# MCXN947_cm33_core0 register map
Vendor: nxp.com; File version: 1.0
CPU: CM33 r2p0, little endian, MPU, FPU, VTOR, 3 interrupt priority bits
Registers are 32-bit, read-write, reset 0x0 unless marked. A register's access mark holds for its fields unless they carry their own. Offsets are from the block's base; [hi:lo] are bit positions; {n}, {i} and the like mark numbered series; 'fields as' and 'values as' point back to an identical list.

## FLEXSPI0 — FlexSPI
Base 0x400C8000
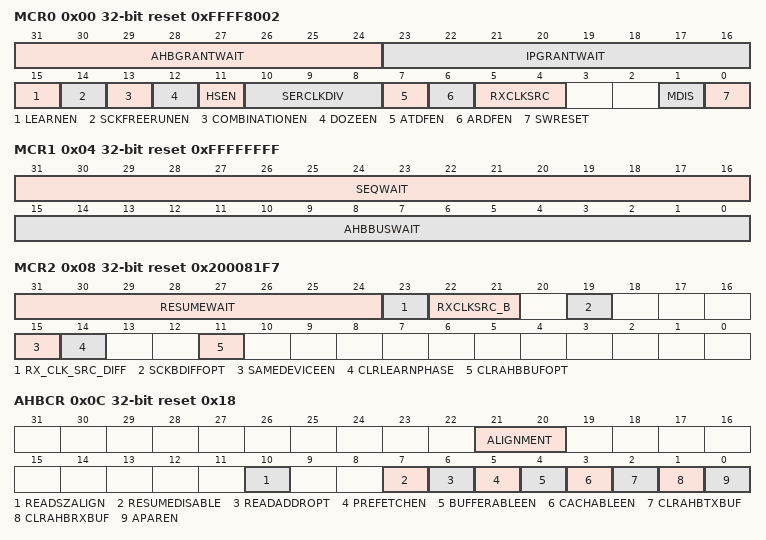
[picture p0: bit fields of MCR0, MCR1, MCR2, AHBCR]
0x00 MCR0 reset 0xFFFF8002 — Module Control 0
  [31:24] AHBGRANTWAIT — Timeouts Wait Cycle for AHB command Grant
  [23:16] IPGRANTWAIT — Timeout Wait Cycle for IP Command Grant
  [15] LEARNEN — Data Learning Enable
    0=DISABLE; 1=ENABLE
  [14] SCKFREERUNEN — SCLK Free-running Enable
    0=DISABLE; 1=ENABLE
  [13] COMBINATIONEN — Combination Mode Enable
    0=DISABLE; 1=ENABLE
  [12] DOZEEN — Doze Mode Enable
    0=Disable; 1=Enable
  [11] HSEN — Half Speed Serial Flash Memory Access Enable
    0=Disable; 1=Enable
  [10:8] SERCLKDIV — Serial Root Clock Divider
    {v}=Divided by {v+1} (v=0..7)
  [7] ATDFEN — AHB Write Access to IP Transmit FIFO Enable
    0=AHB write access disabled. IP bus writes to IP transmit FIFO. AHB bus write access to IP transmit FIFO memory space produces bus error.; 1=AHB write access enabled. AHB bus writes to IP transmit FIFO. IP Bus write access to IP transmit FIFO memory space is ignored and causes no bus error.
  [6] ARDFEN — AHB Read Access to IP Receive FIFO Enable
    0=AHB read access disabled. IP bus reads IP receive FIFO. AHB Bus read access to IP receive FIFO memory space produces bus error.; 1=AHB read access enabled. AHB bus reads IP receive FIFO. IP Bus read access to IP receive FIFO memory space returns data zero and causes no bus error.
  [5:4] RXCLKSRC — Sample Clock Source for Flash Reading
    0=Dummy Read strobe that FlexSPI generates, looped back internally; 1=Dummy Read strobe that FlexSPI generates, looped back from DQS pad; 2=SCLK output clock and looped back from SCLK pad; 3=Flash-memory-provided read strobe and input from DQS pad
  [1] MDIS — Module Disable
    0=No impact; 1=Module disable
  [0] SWRESET — Software Reset
    0=No impact; 1=Software reset
0x04 MCR1 reset 0xFFFFFFFF — Module Control 1
  [31:16] SEQWAIT — Command Sequence Wait
  [15:0] AHBBUSWAIT
0x08 MCR2 reset 0x200081F7 — Module Control 2
  [31:24] RESUMEWAIT — Resume Wait Duration
  [23] RX_CLK_SRC_DIFF — Sample Clock Source Different
    0=Use MCR0[RXCLKSRC] for Port A and Port B; 1=Use MCR0[RXCLKSRC] for Port A, and MCR2[RXCLKSRC_B] for Port B
  [22:21] RXCLKSRC_B — Port B Receiver Clock Source
    0=Dummy read strobe that FlexSPI generates, looped back internally; 1=Dummy read strobe that FlexSPI generates, looped back from DQS pad; 2=SCLK output clock and looped back from SCLK pad; 3=Flash-memory-provided read strobe and input from DQS pad
  [19] SCKBDIFFOPT — SCLK Port B Differential Output
    0=Use B_SCLK pad as port B SCLK clock output. Port B flash memory access is available.; 1=Use B_SCLK pad as port A SCLK inverted clock output (Differential clock to A_SCLK). Port B flash memory access is not available.
  [15] SAMEDEVICEEN — Same Device Enable
    0=individual_parallel (In Individual mode, FLSHA1CRx and FLSHA2CRx, FLSHB1CRx and FLSHB2CRx settings are applied to Flash A1, A2, B1, B2 separately. In Parallel mode, FLSHA1CRx register setting is applied to Flash A1 and B1, FLSHA2CRx register setting is applied to Flash A2 and B2. FLSHB1CRx and FLSHB2CRx register settings are ignored.); 1=ENABLE (FLSHA1CR0, FLSHA1CR1, and FLSHA1CR2 register settings are applied to Flash A1, A2, B1, B2. FLSHA2CRx, FLSHB1CRx, and FLSHB2CRx settings are ignored.)
  [14] CLRLEARNPHASE — Clear Learn Phase Selection
    0=No impact; 1=Reset sample clock phase selection to 0
  [11] CLRAHBBUFOPT — Clear AHB Buffer
    0=Not cleared automatically; 1=Cleared automatically
0x0C AHBCR reset 0x18 — AHB Bus Control
  [21:20] ALIGNMENT — AHB Boundary Alignment
    0=bit0 (No limit); 1=bit1 (1 KB); 2=bit2 (512 bytes); 3=bit3 (256 bytes)
  [10] READSZALIGN — AHB Read Size Alignment
    0=Register settings such as PREFETCH_EN determine AHB read size; 1=AHB read size to up size to 8 bytes aligned, no prefetching
  [7] RESUMEDISABLE — AHB Read Resume Disable
    0=Suspended AHB read prefetch resumes when AHB is IDLE; 1=Suspended AHB read prefetch does not resume once aborted,
  [6] READADDROPT — AHB Read Address Option
    0=AHB read burst start address alignment is limited when flash memory is accessed in parallel mode or flash is word-addressable; 1=AHB read burst start address alignment is not limited. FlexSPI fetches more data than the AHB burst requires for address alignment.
  [5] PREFETCHEN — AHB Read Prefetch Enable
    0=Disable; 1=Enable
  [4] BUFFERABLEEN — Bufferable Write Access Enable
    0=Disabled. For all AHB write accesses (bufferable or nonbufferable), FlexSPI returns AHB Bus Ready after transmitting all data and finishing command.; 1=Enabled. For AHB bufferable write access, FlexSPI returns AHB Bus Ready when the arbitrator grants the AHB command. FlexSPI does not wait for the AHB command to finish.
  [3] CACHABLEEN — Cacheable Read Access Enable
    0=Disabled. When an AHB bus cacheable read access occurs, FlexSPI does not check whether it hit the AHB transmit buffer.; 1=Enabled. When an AHB bus cacheable read access occurs, FlexSPI first checks whether the access hit the AHB transmit buffer.
  [2] CLRAHBTXBUF — Clear AHB Transmit Buffer
    0=No impact; 1=Enable clear operation
  [1] CLRAHBRXBUF — Clear AHB Receive Buffer
    0=No impact; 1=Enable clear operation
  [0] APAREN — AHB Parallel Mode Enable
    0=individual (Flash is accessed in Individual mode.); 1=ENABLE (Flash is accessed in Parallel mode.)
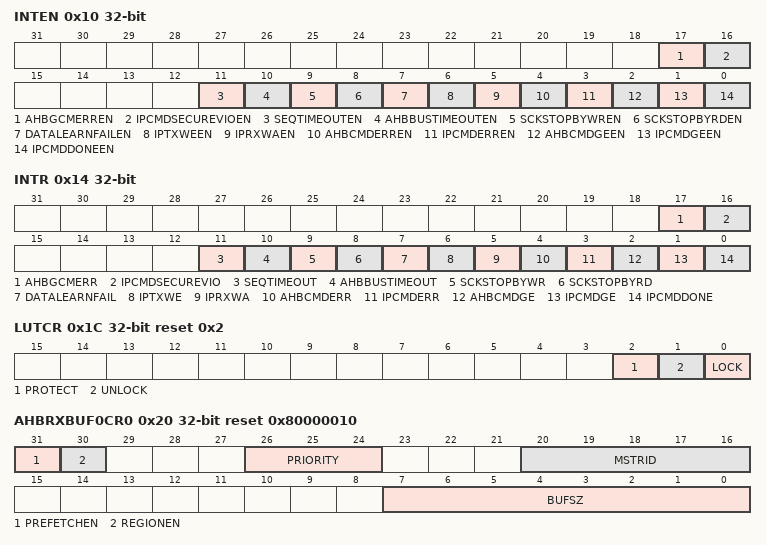
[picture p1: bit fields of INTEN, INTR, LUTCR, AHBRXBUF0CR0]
0x10 INTEN — Interrupt Enable
  [all] fields
    0=Disable interrupt or no impact; 1=Enable interrupt
  [17] AHBGCMERREN — AHB Read GCM Error Interrupt Enable
  [16] IPCMDSECUREVIOEN — IP Command Security Violation Interrupt Enable
  [11] SEQTIMEOUTEN — Sequence execution Timeout Interrupt Enable
  [10] AHBBUSTIMEOUTEN — AHB Bus Timeout Interrupt Enable
  [9] SCKSTOPBYWREN — SCLK Stopped By Write Interrupt Enable
  [8] SCKSTOPBYRDEN — SCLK Stopped By Read Interrupt Enable
  [7] DATALEARNFAILEN — Data Learning Failed Interrupt Enable
  [6] IPTXWEEN — IP Transmit FIFO Watermark Empty Interrupt Enable
  [5] IPRXWAEN — IP Receive FIFO Watermark Available Interrupt Enable
  [4] AHBCMDERREN — AHB-Triggered Command Sequences Error Detected Interrupt Enable
  [3] IPCMDERREN — IP-Triggered Command Sequences Error Detected Interrupt Enable
  [2] AHBCMDGEEN — AHB-Triggered Command Sequences Grant Timeout Interrupt Enable.
  [1] IPCMDGEEN — IP-Triggered Command Sequences Grant Timeout Interrupt Enable
  [0] IPCMDDONEEN — IP-Triggered Command Sequences Execution Finished Interrupt Enable
0x14 INTR write-1-clears — Interrupt
  [all] fields
    on read: 0=NO_INTERRUPT (Interrupt condition has not occurred); 1=INTERRUPT (Interrupt condition has occurred)
  [17] AHBGCMERR write-1-clears — AHB Read GCM Error
  [16] IPCMDSECUREVIO write-1-clears — IP Command Security Violation
  [11] SEQTIMEOUT write-1-clears — Sequence Execution Timeout
  [10] AHBBUSTIMEOUT write-1-clears
  [9] SCKSTOPBYWR write-1-clears — SCLK Stopped Due To Empty Transmit FIFO
  [8] SCKSTOPBYRD write-1-clears — SCLK Stopped Due To Full Receive FIFO
  [7] DATALEARNFAIL write-1-clears — Data Learning Failed
  [6] IPTXWE write-1-clears — IP Transmit FIFO Watermark Empty
  [5] IPRXWA write-1-clears — IP Receive FIFO Watermark Available
  [4] AHBCMDERR write-1-clears — AHB-Triggered Command Sequences Error
  [3] IPCMDERR write-1-clears — IP-Triggered Command Sequences Error
  [2] AHBCMDGE write-1-clears — AHB-Triggered Command Sequences Grant Timeout
  [1] IPCMDGE write-1-clears — IP-Triggered Command Sequences Grant Timeout
  [0] IPCMDDONE write-1-clears — IP-Triggered Command Sequences Execution Finished
0x18 LUTKEY reset 0x5AF05AF0
  [31:0] KEY
0x1C LUTCR reset 0x2 — LUT Control
  [2] PROTECT — LUT Protection
    0=Not protected. All IPS controllers can access LUTCR and LUT memory.; 1=Protected. Only secure IPS controller can change the value of LUTCR and write to LUT memory.
  [1] UNLOCK — Unlock LUT
    0=LUT is locked (LUTCR[LOCK] must be 1); 1=LUT is unlocked and can be written
  [0] LOCK — Lock LUT
    0=LUT is unlocked (LUTCR[UNLOCK] must be 1); 1=LUT is locked and cannot be written
0x20 AHBRXBUF0CR0 reset 0x80000010 — AHB Receive Buffer 0 Control 0
  [31] PREFETCHEN — AHB Read Prefetch Enable
    0=Disabled; 1=Enabled when is enabled
  [30] REGIONEN — AHB Receive Buffer Address Region Enable
    0=Disabled. The buffer hit is based on the value of MSTRID only.; 1=Enabled. The buffer hit is based on the value of MSTRID and the address within AHBBUFREGIONSTARTn and AHBREGIONENDn.
  [26:24] PRIORITY — AHB Controller Read Priority
  [20:16] MSTRID — AHB Controller ID
  [7:0] BUFSZ — AHB Receive Buffer Size
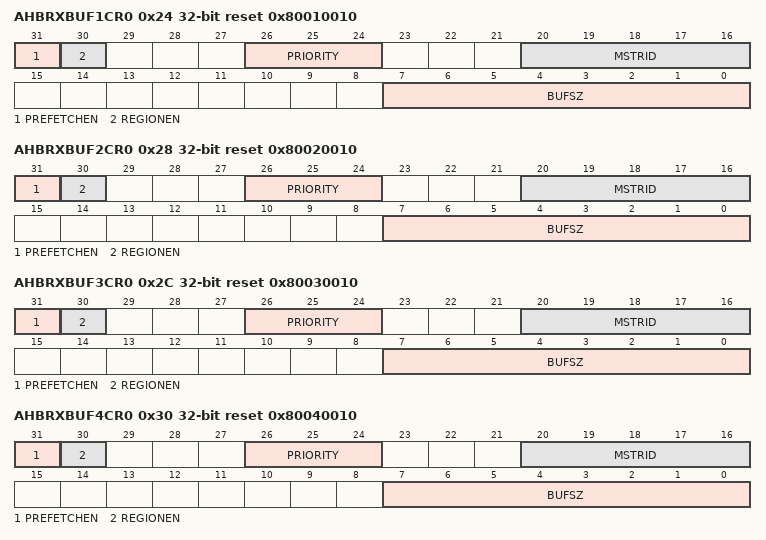
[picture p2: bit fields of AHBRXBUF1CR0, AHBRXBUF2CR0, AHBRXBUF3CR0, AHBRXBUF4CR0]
0x24 AHBRXBUF1CR0 reset 0x80010010 — AHB Receive Buffer 1 Control 0
  fields as AHBRXBUF0CR0
0x28 AHBRXBUF2CR0 reset 0x80020010 — AHB Receive Buffer 2 Control 0
  fields as AHBRXBUF0CR0
0x2C AHBRXBUF3CR0 reset 0x80030010 — AHB Receive Buffer 3 Control 0
  fields as AHBRXBUF0CR0
0x30 AHBRXBUF4CR0 reset 0x80040010 — AHB Receive Buffer 4 Control 0
  fields as AHBRXBUF0CR0
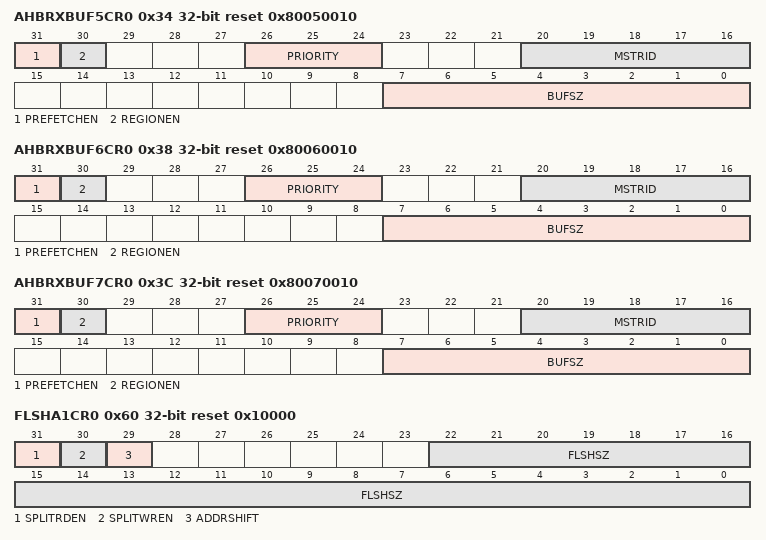
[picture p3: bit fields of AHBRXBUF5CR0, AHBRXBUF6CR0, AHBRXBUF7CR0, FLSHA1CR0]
0x34 AHBRXBUF5CR0 reset 0x80050010 — AHB Receive Buffer 5 Control 0
  fields as AHBRXBUF0CR0
0x38 AHBRXBUF6CR0 reset 0x80060010 — AHB Receive Buffer 6 Control 0
  fields as AHBRXBUF0CR0
0x3C AHBRXBUF7CR0 reset 0x80070010 — AHB Receive Buffer 7 Control 0
  fields as AHBRXBUF0CR0
0x60 FLSHA1CR0 reset 0x10000 — Flash Control 0
  [31] SPLITRDEN — AHB Read Access Split Function Enable
    0=DISABLE; 1=ENABLE
  [30] SPLITWREN — AHB Write Access Split Function Enable
    0=DISABLE; 1=ENABLE
  [29] ADDRSHIFT — AHB Address Shift Function control
    0=DISABLE (Disabled); 1=ENABLE (Enabled)
  [22:0] FLSHSZ — Flash Size in KB
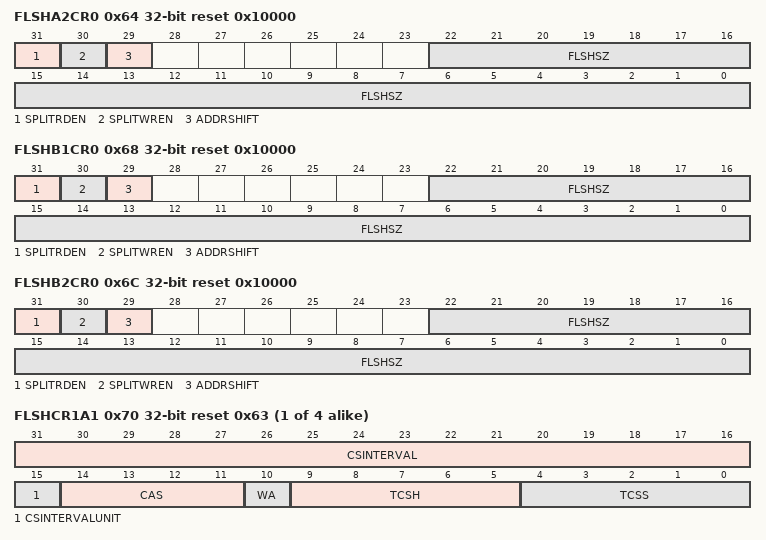
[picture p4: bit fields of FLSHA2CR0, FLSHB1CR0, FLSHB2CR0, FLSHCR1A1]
0x64 FLSHA2CR0 reset 0x10000 — Flash Control 0
  fields as FLSHA1CR0
0x68 FLSHB1CR0 reset 0x10000 — Flash Control 0
  fields as FLSHA1CR0
0x6C FLSHB2CR0 reset 0x10000 — Flash Control 0
  fields as FLSHA1CR0
0x70 FLSHCR1{x} (x=A1,A2,B1,B2; step 0x4) reset 0x63 — Flash Control 1
  [31:16] CSINTERVAL — Chip Select Interval
  [15] CSINTERVALUNIT — Chip Select Interval Unit
    0=1 serial clock cycle; 1=256 serial clock cycles
  [14:11] CAS — Column Address Size
  [10] WA — Word-Addressable
    0=Byte-addressable; 1=Word-addressable
  [9:5] TCSH — Serial Flash CS Hold Time
  [4:0] TCSS — Serial Flash CS Setup Time
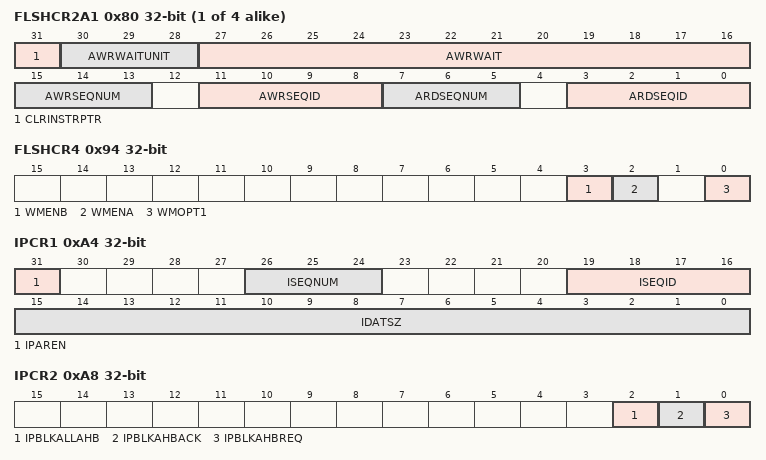
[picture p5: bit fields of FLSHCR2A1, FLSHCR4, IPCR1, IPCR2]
0x80 FLSHCR2{x} (x=A1,A2,B1,B2; step 0x4) — Flash Control 2
  [31] CLRINSTRPTR — Clear Instruction Pointer
  [30:28] AWRWAITUNIT
    0=2; 1=8; 2=32; 3=128; 4=512; 5=2048; 6=8192; 7=32768
  [27:16] AWRWAIT — AHB Write Wait
  [15:13] AWRSEQNUM — Sequence Number for AHB Write-Triggered Command
  [11:8] AWRSEQID — Sequence Index for AHB Write-Triggered Command
  [7:5] ARDSEQNUM — Sequence Number for AHB Read-Triggered Command
  [3:0] ARDSEQID — Sequence Index for AHB Read-Triggered Command in LUT
0x94 FLSHCR4 — Flash Control 4
  [3] WMENB — Write Mask Enable for Port B
    0=Disabled. When writing to external device, DQS(RWDS) pin is not driven.; 1=Enabled. When writing to external device, FlexSPI drives DQS(RWDS) pin as write mask output.
  [2] WMENA — Write Mask Enable for Port A
    values as WMENB
  [0] WMOPT1 — Write Mask Option 1
    0=DISABLE (When writing to an external device, DQS pin is used as write mask. When flash memory is accessed in individual mode, AHB or IP write burst start address alignment is not limited.); 1=ENABLE (When writing to an external device, DQS pin is not used as write mask. When flash memory is accessed in individual mode, AHB or IP write burst start address alignment is limited.)
0xA0 IPCR0 — IP Control 0
  [31:0] SFAR — Serial Flash Address
0xA4 IPCR1 — IP Control 1
  [31] IPAREN — Parallel Mode Enable for IP Commands
    0=DISABLE (Disabled. Flash memory is accessed in Individual mode.); 1=ENABLE (Enabled. Flash memory is accessed in Parallel mode.)
  [26:24] ISEQNUM — Sequence Number for IP command: ISEQNUM+1.
  [19:16] ISEQID — Sequence Index in LUT for IP command.
  [15:0] IDATSZ — Flash Read/Program Data Size (in bytes) for IP command.
0xA8 IPCR2 — IP Control 2
  [2] IPBLKALLAHB — IP Command Blocking All AHB Command Enable
    0=IP commands only block AHB commands that affect the IPED region; 1=IP commands block all AHB commands
  [1] IPBLKAHBACK ro — IP Command Blocking AHB Command Acknowledgment Enable
    0=IP commands do not block AHB command acknowledgment; 1=IP commands block AHB command acknowledgment
  [0] IPBLKAHBREQ — IP Command Blocking AHB Command Request Enable
    0=IP commands do not block AHB command requests; 1=IP commands block AHB command requests
0xB0 IPCMD — IP Command
  [0] TRG — Command Trigger
    0=No action; 1=Start the IP command that the IPCR0 and IPCR1 registers define
0xB4 DLPR — Data Learning Pattern
  [31:0] DLP
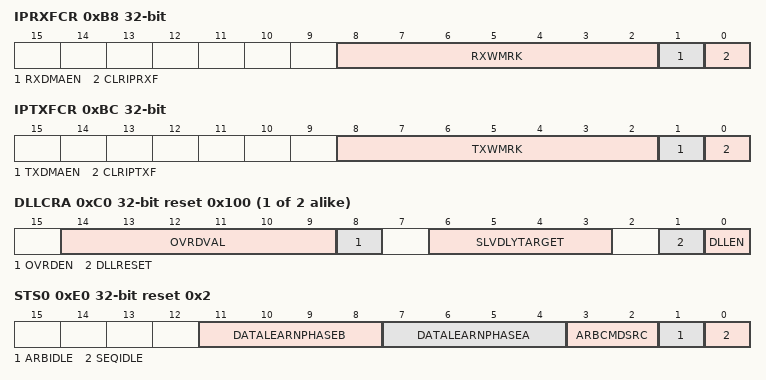
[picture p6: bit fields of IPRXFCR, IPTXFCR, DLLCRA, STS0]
0xB8 IPRXFCR — IP Receive FIFO Control
  [8:2] RXWMRK — IP Receive FIFO Watermark Level
  [1] RXDMAEN — IP Receive FIFO Reading by DMA Enable
    0=Disabled. The processor reads the FIFO.; 1=Enabled. DMA reads the FIFO.
  [0] CLRIPRXF — Clear IP Receive FIFO
    0=No function; 1=A clock cycle pulse clears all valid data entries in IP receive FIFO
0xBC IPTXFCR — IP Transmit FIFO Control
  [8:2] TXWMRK — Transmit Watermark Level
  [1] TXDMAEN — Transmit FIFO DMA Enable
    0=Processor; 1=DMA
  [0] CLRIPTXF — Clear IP Transmit FIFO
    0=No function; 1=A clock cycle pulse clears all valid data entries in the IP transmit FIFO
0xC0 DLLCR{x} (x=A,B; step 0x4) reset 0x100 — DLL Control 0
  [14:9] OVRDVAL — Target Clock Delay Line Override Value
  [8] OVRDEN — Target Clock Delay Line Override Value Enable
    0=Disable; 1=Enable
  [6:3] SLVDLYTARGET — Target Delay Line For Target
  [1] DLLRESET
    0=No function; 1=Force DLL reset
  [0] DLLEN — DLL Calibration Enable
    0=Disable; 1=Enable
0xE0 STS0 ro reset 0x2 — Status 0
  [11:8] DATALEARNPHASEB — Data Learning Phase Selection on Port B
  [7:4] DATALEARNPHASEA — Data Learning Phase Selection on Port A
  [3:2] ARBCMDSRC — ARB Command Source
    0=Trigger source is AHB read command; 1=Trigger source is AHB write command; 2=Trigger source is IP command (by writing 1 to IPCMD[TRG]); 3=Trigger source is a suspended command that has resumed
  [1] ARBIDLE — ARB_CTL State Machine Idle
    0=Not idle; 1=Idle
  [0] SEQIDLE — SEQ_CTL State Machine Idle
    0=Not idle; 1=Idle
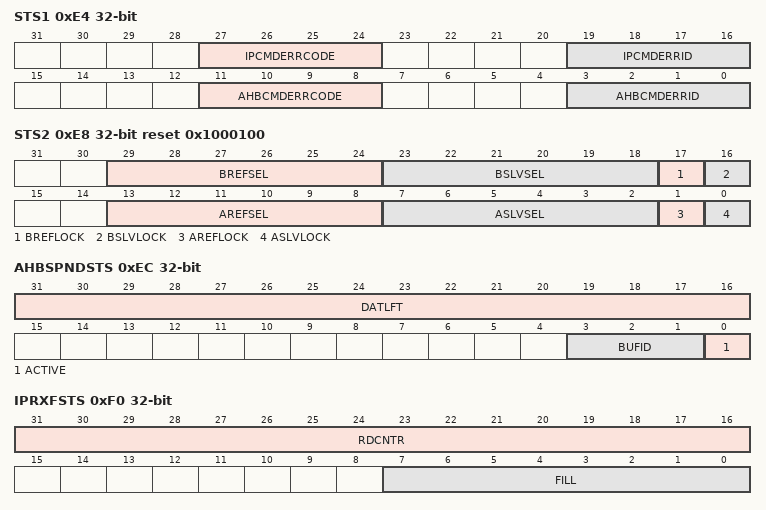
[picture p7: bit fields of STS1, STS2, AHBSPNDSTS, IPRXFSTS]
0xE4 STS1 ro — Status 1
  [27:24] IPCMDERRCODE — IP Command Error Code
    0=No error; 2=IP command with JMP_ON_CS instruction used in the sequence; 3=Unknown instruction opcode in the sequence; 4=DUMMY_SDR or DUMMY_RWDS_SDR instruction used in DDR sequence; 5=DUMMY_DDR or DUMMY_RWDS_DDR instruction used in SDR sequence; 6=Flash memory access start address exceeds entire flash address range (A1, A2, B1, and B2); 14=Sequence execution timeout; 15=Flash boundary crossed
  [19:16] IPCMDERRID — IP Command Error ID
  [11:8] AHBCMDERRCODE — AHB Command Error Code
    0=No error; 2=AHB Write command with JMP_ON_CS instruction used in the sequence; 3=Unknown instruction opcode in the sequence; 4=DUMMY_SDR or DUMMY_RWDS_SDR instruction used in DDR sequence; 5=DUMMY_DDR or DUMMY_RWDS_DDR instruction used in SDR sequence; 14=Sequence execution timeout
  [3:0] AHBCMDERRID — AHB Command Error ID
0xE8 STS2 ro reset 0x1000100 — Status 2
  [29:24] BREFSEL — Flash B Sample Clock Reference Delay Line Delay Cell Number
  [23:18] BSLVSEL — Flash B Sample Clock Target Delay Line Delay Cell Number
  [17] BREFLOCK — Flash B Sample Clock Reference Delay Line Locked
    0=Not locked; 1=Locked
  [16] BSLVLOCK — Flash B Sample Target Reference Delay Line Locked
    0=Not locked; 1=Locked
  [13:8] AREFSEL — Flash A Sample Clock Reference Delay Line Delay Cell Number
  [7:2] ASLVSEL — Flash A Sample Clock Target Delay Line Delay Cell Number
  [1] AREFLOCK — Flash A Sample Clock Reference Delay Line Locked
    0=Not locked; 1=Locked
  [0] ASLVLOCK — Flash A Sample Target Delay Line Locked
    0=Not locked; 1=Locked
0xEC AHBSPNDSTS ro — AHB Suspend Status
  [31:16] DATLFT — Data Left
  [3:1] BUFID — AHB Receive Buffer ID for Suspended Command Sequence
  [0] ACTIVE — Active AHB Read Prefetch Suspended
    0=No suspended AHB read prefetch command; 1=An AHB read prefetch command sequence has been suspended
0xF0 IPRXFSTS ro — IP Receive FIFO Status
  [31:16] RDCNTR — Read Data Counter
  [7:0] FILL — Fill Level of IP Receive FIFO
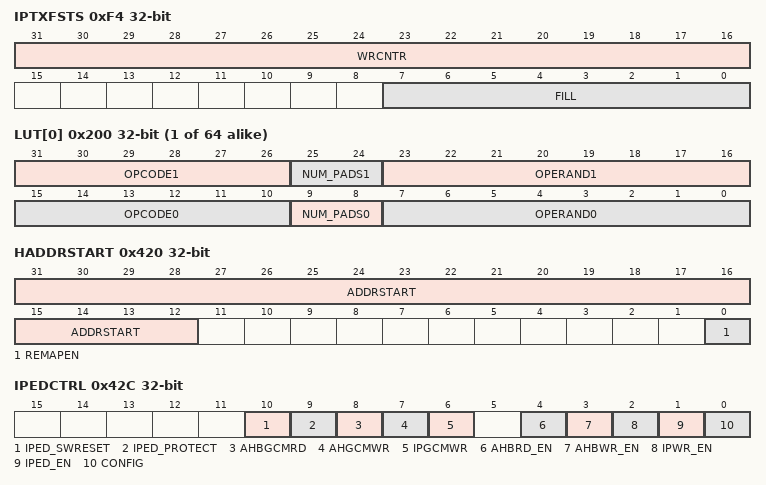
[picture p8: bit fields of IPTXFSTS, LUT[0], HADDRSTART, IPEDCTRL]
0xF4 IPTXFSTS ro — IP Transmit FIFO Status
  [31:16] WRCNTR — Write Data Counter
  [7:0] FILL — Fill Level of IP Transmit FIFO
{0x100+4i} RFDR[{i}] (i=0..31) ro reset not defined — IP Receive FIFO Data x
  [31:0] RXDATA — Receive Data
{0x180+4i} TFDR[{i}] (i=0..31) wo — IP TX FIFO Data x
  [31:0] TXDATA — Transmit Data
{0x200+4i} LUT[{i}] (i=0..63) reset not defined — Lookup Table x
  [31:26] OPCODE1
  [25:24] NUM_PADS1
  [23:16] OPERAND1
  [15:10] OPCODE0 — OPCODE
  [9:8] NUM_PADS0
  [7:0] OPERAND0
0x420 HADDRSTART — HADDR REMAP Start Address
  [31:12] ADDRSTART — HADDR Start Address
  [0] REMAPEN — AHB Bus Address Remap Enable
    0=HADDR REMAP Disabled; 1=HADDR REMAP Enabled
0x424 HADDREND — HADDR REMAP END ADDR
  [31:12] ENDSTART — End Address of HADDR Remap Range
0x428 HADDROFFSET — HADDR Remap Offset
  [31:12] ADDROFFSET — HADDR Offset
0x42C IPEDCTRL — IPED Function Control
  [10] IPED_SWRESET — Abort Current Decryption or Encryption
    0=No function; 1=Aborts current decryption or encryption and waits for the next start operation
  [9] IPED_PROTECT — IPED Protection
    0=No restrictions; 1=Only privileged controllers can write IPED registers
  [8] AHBGCMRD — AHB Read IPED GCM Mode Decryption Enable
    0=Disable; 1=Enable
  [7] AHGCMWR — AHB Write IPED GCM Mode Encryption Enable
    0=Disable; 1=Enable
  [6] IPGCMWR — IP Write GCM Mode Enable
    0=Disabled; 1=Enabled
  [4] AHBRD_EN — AHB Read IPED CTR Mode Decryption Enable
    0=Disable; 1=Enable
  [3] AHBWR_EN — AHB Write IPED CTR Mode Encryption Enable.
    0=Disable; 1=Enable
  [2] IPWR_EN — IP Write IPED CTR Mode Encryption Enable
    0=Disable; 1=Enable
  [1] IPED_EN — IPED Encryption and Decryption Enable
    0=Disable; 1=Enable
  [0] CONFIG — IPED Mode Select
    0=Fully pipelined; 1=Not fully pipelined
0x430 IPSNSZSTART0 — IPS Nonsecure Region 0 Start Address
  [31:12] start_address — Start Address of Nonsecure Region
0x434 IPSNSZEND0 — IPS Nonsecure Region 0 End Address
  [31:12] end_address — End Address of Nonsecure Region
0x438 IPSNSZSTART1 — IPS Nonsecure Region 1 Start Address
  [31:12] start_address — Start Address of Nonsecure Region
0x43C IPSNSZEND1 — IPS Nonsecure Region 1 End Address
  [31:12] end_address — End Address of Nonsecure Region
{0x440+8i} AHBBUFREGIONSTART{i} (i=0..3) — Receive Buffer Start Address of Region {i}
  [31:12] START_ADDRESS — Start Address of Prefetch Sub-Buffer Region
{0x444+8i} AHBBUFREGIONEND{i} (i=0..3) — Receive Buffer Region {i} End Address
  [31:12] END_ADDRESS — End Address of Prefetch Sub-Buffer Region
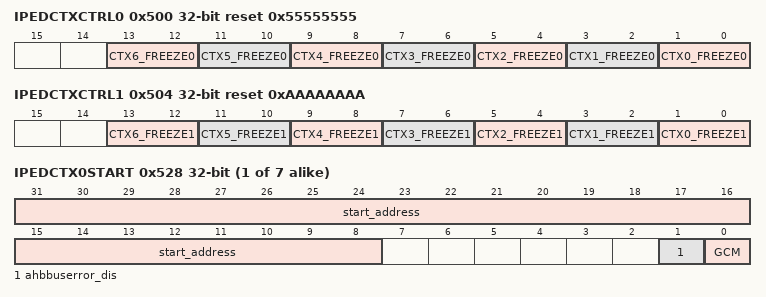
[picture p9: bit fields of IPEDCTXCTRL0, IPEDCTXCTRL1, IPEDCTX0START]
0x500 IPEDCTXCTRL0 reset 0x55555555 — IPED context control 0
  [2n+1:2n] CTX{n}_FREEZE0 (n=0..6) — Context Register Freeze for Region {n}
0x504 IPEDCTXCTRL1 reset 0xAAAAAAAA — IPED context control 1
  [2n+1:2n] CTX{n}_FREEZE1 (n=0..6) — Context Register Freeze for Region {n}
{0x520+0x20*i} IPEDCTX{i}IV0 (i=0..6) — IPED Context{i} IV0
  [31:0] CTX{i}_IV0 — Lowest 32 bits of IV for region {i}.
{0x524+0x20*i} IPEDCTX{i}IV1 (i=0..6) — IPED Context{i} IV1
  [31:0] CTX{i}_IV1 — Highest 32 bits of IV for region {i}.
{0x528+0x20*i} IPEDCTX{i}START (i=0..6) — Start Address of Region
  [31:8] start_address
  [1] ahbbuserror_dis — AHB Bus Error Disable
    0=AHB bus errors enabled; 1=AHB bus errors disabled
  [0] GCM — GCM Mode Enable
    0=Disabled. CTR mode is used.; 1=Enabled. GCM mode is used.
{0x52C+0x20*i} IPEDCTX{i}END (i=0..6) — End Address of Region
  [31:8] end_address — End Address of IPED Region
{0x530+0x20*i} IPEDCTX{i}AAD0 (i=0..6) — IPED Context{i} Additional Authenticated Data0
  [31:0] CTX{i}_AAD0 — CTX AAD
{0x534+0x20*i} IPEDCTX{i}AAD1 (i=0..6) — IPED Context{i} Additional Authenticated Data1
  [31:0] CTX{i}_AAD1 — CTX AAD
